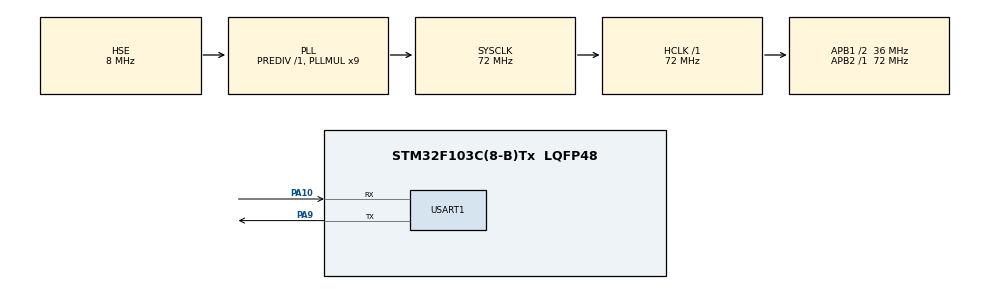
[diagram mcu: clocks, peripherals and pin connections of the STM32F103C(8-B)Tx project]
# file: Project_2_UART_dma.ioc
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Dma.Request0=USART1_TX
Dma.Request1=USART1_RX
Dma.USART1_RX.1.Direction=DMA_PERIPH_TO_MEMORY
Dma.USART1_RX.1.Instance=DMA1_Channel5
Dma.USART1_RX.1.MemDataAlignment=DMA_MDATAALIGN_BYTE
Dma.USART1_RX.1.MemInc=DMA_MINC_ENABLE
Dma.USART1_RX.1.Mode=DMA_CIRCULAR
Dma.USART1_RX.1.PeriphDataAlignment=DMA_PDATAALIGN_BYTE
Dma.USART1_RX.1.PeriphInc=DMA_PINC_DISABLE
Dma.USART1_RX.1.Priority=DMA_PRIORITY_LOW
Dma.USART1_TX.0.Direction=DMA_MEMORY_TO_PERIPH
Dma.USART1_TX.0.Instance=DMA1_Channel4
Dma.USART1_TX.0.MemDataAlignment=DMA_MDATAALIGN_BYTE
Dma.USART1_TX.0.MemInc=DMA_MINC_ENABLE
Dma.USART1_TX.0.Mode=DMA_NORMAL
Dma.USART1_TX.0.PeriphDataAlignment=DMA_PDATAALIGN_BYTE
Dma.USART1_TX.0.PeriphInc=DMA_PINC_DISABLE
Dma.USART1_TX.0.Priority=DMA_PRIORITY_LOW
Mcu.Family=STM32F1
Mcu.Name=STM32F103C(8-B)Tx
Mcu.Package=LQFP48
NVIC.DMA1_Channel4_IRQn=true\:0\:0\:false\:false\:true\:false\:true\:true
NVIC.DMA1_Channel5_IRQn=true\:0\:0\:false\:false\:true\:false\:true\:true
NVIC.PriorityGroup=NVIC_PRIORITYGROUP_4
NVIC.USART1_IRQn=true\:0\:0\:false\:false\:true\:true\:true\:true
PA10.Mode=Asynchronous
PA10.Signal=USART1_RX
PA13.Mode=Serial_Wire
PA13.Signal=SYS_JTMS-SWDIO
PA14.Mode=Serial_Wire
PA14.Signal=SYS_JTCK-SWCLK
PA9.Mode=Asynchronous
PA9.Signal=USART1_TX
PD0-OSC_IN.Mode=HSE-External-Oscillator
PD0-OSC_IN.Signal=RCC_OSC_IN
PD1-OSC_OUT.Mode=HSE-External-Oscillator
PD1-OSC_OUT.Signal=RCC_OSC_OUT
ProjectManager.HeapSize=0x200
ProjectManager.StackSize=0x400
ProjectManager.TargetToolchain=MDK-ARM V5.32
RCC.AHBFreq_Value=72000000
RCC.APB1CLKDivider=RCC_HCLK_DIV2
RCC.APB1Freq_Value=36000000
RCC.APB1TimFreq_Value=72000000
RCC.APB2Freq_Value=72000000
RCC.APB2TimFreq_Value=72000000
RCC.HCLKFreq_Value=72000000
RCC.PLLMUL=RCC_PLL_MUL9
RCC.PLLSourceVirtual=RCC_PLLSOURCE_HSE
RCC.SYSCLKFreq_VALUE=72000000
RCC.SYSCLKSource=RCC_SYSCLKSOURCE_PLLCLK
RCC.USBFreq_Value=72000000
USART1.VirtualMode=VM_ASYNC
board=custom

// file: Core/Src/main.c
/* USER CODE BEGIN Header */
/**
  ******************************************************************************
  * @file           : main.c
  * @brief          : Main program body
  ******************************************************************************
  * @attention
  *
  * Copyright (c) 2026 STMicroelectronics.
  * All rights reserved.
  *
  * This software is licensed under terms that can be found in the LICENSE file
  * in the root directory of this software component.
  * If no LICENSE file comes with this software, it is provided AS-IS.
  *
  ******************************************************************************
  */
/* USER CODE END Header */
#include "main.h"
/* USER CODE BEGIN Includes */
#include <stdio.h>
#include <string.h>
/* USER CODE END Includes */

/* USER CODE BEGIN PD */
#define BUFFER_SIZE 128
#define SAFE_THRESHOLD (BUFFER_SIZE - 10)
/* USER CODE END PD */

UART_HandleTypeDef huart1;
DMA_HandleTypeDef hdma_usart1_tx;
DMA_HandleTypeDef hdma_usart1_rx;

/* USER CODE BEGIN PV */

uint8_t data[BUFFER_SIZE] = {0};

uint8_t head = 0;
uint8_t tail = 0;

uint16_t digit_count = 0;
uint16_t char_count = 0;
uint16_t count = 0;

char str[128];

volatile uint8_t tx_busy = 0;
uint8_t overflow_flag = 0;
uint8_t block_processing = 0; // ?? NEW
UART_HandleTypeDef huart1;

/* USER CODE END PV */

void SystemClock_Config(void);
static void MX_GPIO_Init(void);
static void MX_DMA_Init(void);
static void MX_USART1_UART_Init(void);

/* USER CODE BEGIN 0 */
void HAL_UART_TxCpltCallback(UART_HandleTypeDef *huart) {
	if(huart->Instance == USART1) {
		tx_busy = 0;
	}
}
/* USER CODE END 0 */

int main(void)
{

  /* USER CODE BEGIN 1 */
		uint8_t has_data = 0;
    uint32_t last_rx_time = 0;
    uint16_t distance = 0;

  /* USER CODE END 1 */

  /* MCU Configuration--------------------------------------------------------*/

  /* Reset of all peripherals, Initializes the Flash interface and the Systick. */
  HAL_Init();

  /* Configure the system clock */
  SystemClock_Config();

  /* Initialize all configured peripherals */
  MX_GPIO_Init();
  MX_DMA_Init();
  MX_USART1_UART_Init();
  /* USER CODE BEGIN 2 */
	HAL_UART_Receive_DMA(&huart1, data, BUFFER_SIZE);
  /* USER CODE END 2 */

  /* Infinite loop */
  while (1)
  {
				head = BUFFER_SIZE - __HAL_DMA_GET_COUNTER(&hdma_usart1_rx);

        distance = (head >= tail)
                 ? (head - tail)
                 : (BUFFER_SIZE - tail + head);

        // =========================
        // ?? 1. OVERFLOW HANDLING
        // =========================
        if(distance >= SAFE_THRESHOLD) {
            tail = head;

            overflow_flag = 1;
            block_processing = 1;   // ?? FIX l?i 3

            count = 0;
            digit_count = 0;
            char_count = 0;
            has_data = 0;
        }

        // =========================
        // ?? 2. NORMAL PROCESSING
        // =========================
        else if(head != tail && block_processing == 0) {
            last_rx_time = HAL_GetTick();
            has_data = 1;

            while (tail != head) {

                if(data[tail] >= '0' && data[tail] <= '9') {
                    digit_count++;
                } else {
                    char_count++;
                }

                count++;
                tail = (tail + 1) % BUFFER_SIZE;

            }
        }

        // =========================
        // ?? 3. TX HANDLING
        // =========================
        if(tx_busy == 0) {

            // ?? uu tiên g?i overflow tru?c
            if(overflow_flag == 1) {
                tx_busy = 1; // ?? FIX l?i 2
                HAL_UART_Transmit_DMA(&huart1,
                                      (uint8_t*)"buffer overflow\n",
                                      strlen("buffer overflow\n"));

                overflow_flag = 0;
                block_processing = 0; // ?? unlock sau khi dã x? lý

                continue; // ?? FIX l?i 5: không cho ch?y xu?ng du?i
            }

            // ?? g?i data khi idle
            if( (HAL_GetTick() - last_rx_time >= 10) && has_data == 1 ) {

                int len = sprintf(str,
                    "count: %d\ndigit_count: %d\nchar_count: %d\n",
                    count, digit_count, char_count);

                tx_busy = 1;
                HAL_UART_Transmit_DMA(&huart1, (uint8_t*)str, len);

                has_data = 0;
                count = 0;
                digit_count = 0;
                char_count = 0;
            }
        }
  }
}

void SystemClock_Config(void)
{
  RCC_OscInitTypeDef RCC_OscInitStruct = {0};
  RCC_ClkInitTypeDef RCC_ClkInitStruct = {0};

  /** Initializes the RCC Oscillators according to the specified parameters
  * in the RCC_OscInitTypeDef structure.
  */
  RCC_OscInitStruct.OscillatorType = RCC_OSCILLATORTYPE_HSE;
  RCC_OscInitStruct.HSEState = RCC_HSE_ON;
  RCC_OscInitStruct.HSEPredivValue = RCC_HSE_PREDIV_DIV1;
  RCC_OscInitStruct.HSIState = RCC_HSI_ON;
  RCC_OscInitStruct.PLL.PLLState = RCC_PLL_ON;
  RCC_OscInitStruct.PLL.PLLSource = RCC_PLLSOURCE_HSE;
  RCC_OscInitStruct.PLL.PLLMUL = RCC_PLL_MUL9;
  if (HAL_RCC_OscConfig(&RCC_OscInitStruct) != HAL_OK)
  {
    Error_Handler();
  }

  /** Initializes the CPU, AHB and APB buses clocks
  */
  RCC_ClkInitStruct.ClockType = RCC_CLOCKTYPE_HCLK|RCC_CLOCKTYPE_SYSCLK
                              |RCC_CLOCKTYPE_PCLK1|RCC_CLOCKTYPE_PCLK2;
  RCC_ClkInitStruct.SYSCLKSource = RCC_SYSCLKSOURCE_PLLCLK;
  RCC_ClkInitStruct.AHBCLKDivider = RCC_SYSCLK_DIV1;
  RCC_ClkInitStruct.APB1CLKDivider = RCC_HCLK_DIV2;
  RCC_ClkInitStruct.APB2CLKDivider = RCC_HCLK_DIV1;

  if (HAL_RCC_ClockConfig(&RCC_ClkInitStruct, FLASH_LATENCY_2) != HAL_OK)
  {
    Error_Handler();
  }
}

static void MX_USART1_UART_Init(void)
{

  huart1.Instance = USART1;
  huart1.Init.BaudRate = 115200;
  huart1.Init.WordLength = UART_WORDLENGTH_8B;
  huart1.Init.StopBits = UART_STOPBITS_1;
  huart1.Init.Parity = UART_PARITY_NONE;
  huart1.Init.Mode = UART_MODE_TX_RX;
  huart1.Init.HwFlowCtl = UART_HWCONTROL_NONE;
  huart1.Init.OverSampling = UART_OVERSAMPLING_16;
  if (HAL_UART_Init(&huart1) != HAL_OK)
  {
    Error_Handler();
  }

}

static void MX_DMA_Init(void)
{

  /* DMA controller clock enable */
  __HAL_RCC_DMA1_CLK_ENABLE();

  /* DMA interrupt init */
  /* DMA1_Channel4_IRQn interrupt configuration */
  HAL_NVIC_SetPriority(DMA1_Channel4_IRQn, 0, 0);
  HAL_NVIC_EnableIRQ(DMA1_Channel4_IRQn);
  /* DMA1_Channel5_IRQn interrupt configuration */
  HAL_NVIC_SetPriority(DMA1_Channel5_IRQn, 0, 0);
  HAL_NVIC_EnableIRQ(DMA1_Channel5_IRQn);

}

static void MX_GPIO_Init(void)
{

  /* GPIO Ports Clock Enable */
  __HAL_RCC_GPIOD_CLK_ENABLE();
  __HAL_RCC_GPIOA_CLK_ENABLE();

}

void Error_Handler(void)
{
  __disable_irq();
  while (1)
  {
  }
}
